# PIC32CM1216LS00048 device description
Architecture: CORTEX-M23; Family: PIC32CM; Series: PIC32CMLS00
Registers are 32-bit, read-write, reset 0x0 unless marked. A register's access mark holds for its fields unless they carry their own. Offsets are from the block's base; [hi:lo] are bit positions; {n}, {i} and the like mark numbered series; 'fields as' and 'values as' point back to an identical list; <NAME> marks a mode.

## CoreDebug — Debug Control Block
Instances: CoreDebug 0xE000EDF0, CoreDebug_NS 0xE002EDF0
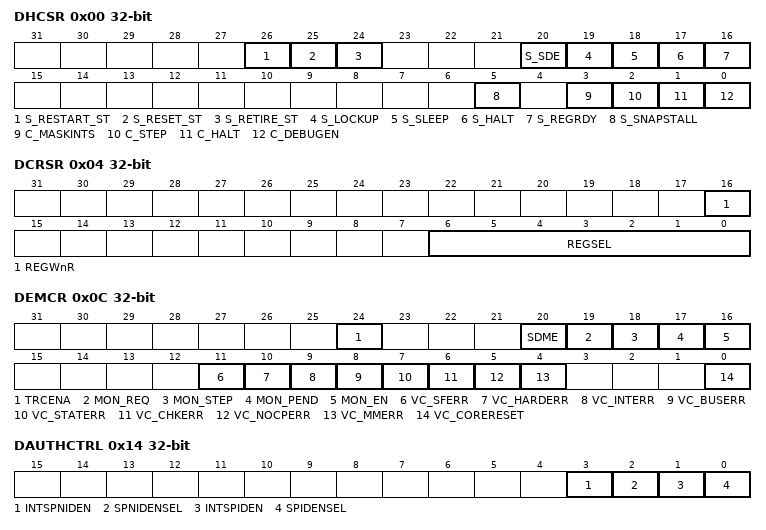
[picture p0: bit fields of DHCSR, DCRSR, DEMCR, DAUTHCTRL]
0x00 DHCSR reset not defined — Debug Halting Control and Status Register
  [26] S_RESTART_ST — Restart sticky status
  [25] S_RESET_ST — Reset sticky status
  [24] S_RETIRE_ST — Retire sticky status
  [20] S_SDE — Secure debug enabled
  [19] S_LOCKUP — Lockup status
  [18] S_SLEEP — Sleeping status
  [17] S_HALT — Halted status
  [16] S_REGRDY — Register ready status
  [5] S_SNAPSTALL — Snap stall control
  [3] C_MASKINTS — Mask PendSV, SysTick and external configurable interrupts
  [2] C_STEP — Enable single step
  [1] C_HALT — Halt processor
  [0] C_DEBUGEN — Enable Halting debug
0x04 DCRSR wo reset not defined — Debug Core Register Select Register
  [16] REGWnR — Register write/not-read access
  [6:0] REGSEL — Register selector
0x0C DEMCR reset not defined — Debug Exception and Monitor Control Register
  [24] TRCENA — Global DWT and ITM features enable
  [20] SDME — Secure DebugMonitor enable
  [19] MON_REQ — DebugMonitor semaphore bit
  [18] MON_STEP — Enable DebugMonitor stepping
  [17] MON_PEND — DebugMonitor pending state
  [16] MON_EN — DebugMonitor enable
  [11] VC_SFERR — SecureFault exception Halting debug vector catch enable
  [10] VC_HARDERR — HardFault exception Halting debug vector catch enable
  [9] VC_INTERR — Excception entry and return faults Halting debug vector catch enable
  [8] VC_BUSERR — BusFault exception Halting debug vector catch enable
  [7] VC_STATERR — UsageFault exception state information error Halting debug vector catch enable
  [6] VC_CHKERR — UsageFault exception checking error Halting debug vector catch enable
  [5] VC_NOCPERR — UsageFault exception coprocessor access Halting debug vector catch enable
  [4] VC_MMERR — MemManage exception Halting debug vector catch enable
  [0] VC_CORERESET — Core reset Halting debug vector catch enable
0x14 DAUTHCTRL reset not defined — Debug Authentication Control Register
  [3] INTSPNIDEN — Internal Secure non-invasive debug enable
  [2] SPNIDENSEL — Secure non-invasive debug enable select
  [1] INTSPIDEN — Internal Secure invasive debug enable
  [0] SPIDENSEL — Secure invasive debug enable select
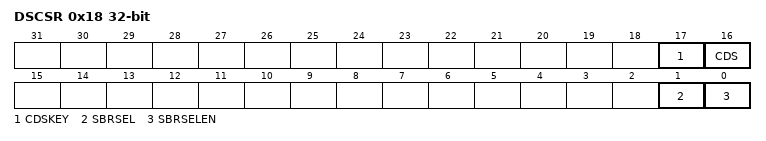
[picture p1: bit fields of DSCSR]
0x18 DSCSR reset not defined — Debug Security Control and Status Register
  [17] CDSKEY — CDS field write-enable key
  [16] CDS — Current domain Secure
  [1] SBRSEL — Secure Banked register select
  [0] SBRSELEN — Secure Banked register select enable

## DAC — Digital-to-Analog Converter
Instances: DAC 0x42003C00
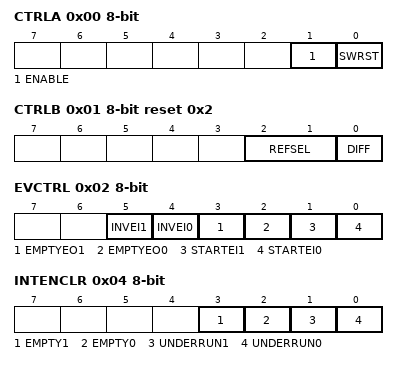
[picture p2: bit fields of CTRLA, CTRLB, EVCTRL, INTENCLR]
0x00 CTRLA 8-bit (WSYNC) — Control A
  [1] ENABLE — Enable DAC Controller
  [0] SWRST — Software Reset
0x01 CTRLB 8-bit reset 0x2 — Control B
  [2:1] REFSEL — Reference Selection for DAC0/1
    0=VREFAU (Unbuffered External Voltage Reference (not buffered in DAC, direct connection)); 1=AVDD (Analog Voltage Supply); 2=VREFAB (Buffered External Voltage Reference (buffered in DAC)); 3=INTREF (Internal Voltage Reference)
  [0] DIFF — Differential mode enable
0x02 EVCTRL 8-bit — Event Control
  [5] INVEI1 — Enable Invertion of DAC 1 input event
  [4] INVEI0 — Enable Invertion of DAC 0 input event
  [3] EMPTYEO1 — Data Buffer Empty Event Output DAC 1
  [2] EMPTYEO0 — Data Buffer Empty Event Output DAC 0
  [1] STARTEI1 — Start Conversion Event Input DAC 1
  [0] STARTEI0 — Start Conversion Event Input DAC 0
0x04 INTENCLR 8-bit (atomic clear) — Interrupt Enable Clear
  [3] EMPTY1 — Data Buffer 1 Empty Interrupt Enable
  [2] EMPTY0 — Data Buffer 0 Empty Interrupt Enable
  [1] UNDERRUN1 — Underrun Interrupt Enable for DAC 1
  [0] UNDERRUN0 — Underrun Interrupt Enable for DAC 0
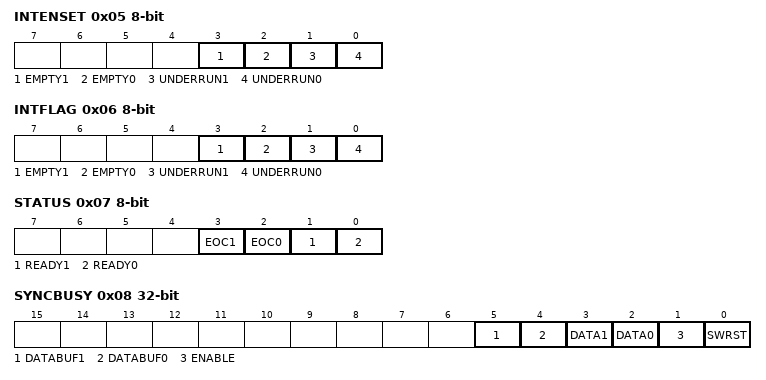
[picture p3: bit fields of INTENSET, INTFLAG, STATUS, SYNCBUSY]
0x05 INTENSET 8-bit (atomic set) — Interrupt Enable Set
  fields as INTENCLR
0x06 INTFLAG 8-bit (atomic clear) — Interrupt Flag Status and Clear
  [3] EMPTY1 — Data Buffer 1 Empty
  [2] EMPTY0 — Data Buffer 0 Empty
  [1] UNDERRUN1 — DAC 1 Underrun
  [0] UNDERRUN0 — DAC 0 Underrun
0x07 STATUS 8-bit ro
  [3] EOC1 — DAC 1 End of Conversion
  [2] EOC0 — DAC 0 End of Conversion
  [1] READY1 — DAC 1 Startup Ready
  [0] READY0 — DAC 0 Startup Ready
0x08 SYNCBUSY ro — Synchronization Busy
  [5] DATABUF1 — Data Buffer DAC 1
  [4] DATABUF0 — Data Buffer DAC 0
  [3] DATA1 — Data DAC 1
  [2] DATA0 — Data DAC 0
  [1] ENABLE — DAC Enable Status
  [0] SWRST — Software Reset
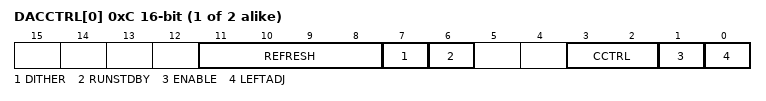
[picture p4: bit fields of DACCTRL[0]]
{0xC+2i} DACCTRL[{i}] (i=0..1) 16-bit — DAC n Control
  [11:8] REFRESH — Refresh period
    0=Do not Refresh; 2=Refresh every 60US; 3=Refresh every 90US; 4=Refresh every 120US; 5=Refresh every 150US; 6=Refresh every 180US; 7=Refresh every 210US; 8=Refresh every 240US; 9=Refresh every 270US; 10=Refresh every 300US; 11=Refresh every 330US; 12=Refresh every 360US; 13=Refresh every 390US; 14=Refresh every 420US; 15=Refresh every 450US
  [7] DITHER — Dithering Mode
  [6] RUNSTDBY — Run in Standby
  [3:2] CCTRL — Current Control
    0=CC100K (GCLK_DAC <= 1.2MHz (100kSPS)); 1=CC1M (1.2MHz < GCLK_DAC <= 6MHz (500kSPS)); 2=CC12M (6MHz < GCLK_DAC <= 12MHz (1MSPS))
  [1] ENABLE — Enable DAC0
  [0] LEFTADJ — Left Adjusted Data
{0x10+2i} DATA[{i}] (i=0..1) 16-bit wo (WSYNC) — DAC n Data
  [15:0] DATA — DAC0 Data
{0x14+2i} DATABUF[{i}] (i=0..1) 16-bit wo (WSYNC) — DAC n Data Buffer
  [15:0] DATABUF — DAC0 Data Buffer
0x18 DBGCTRL 8-bit — Debug Control
  [0] DBGRUN — Debug Run
